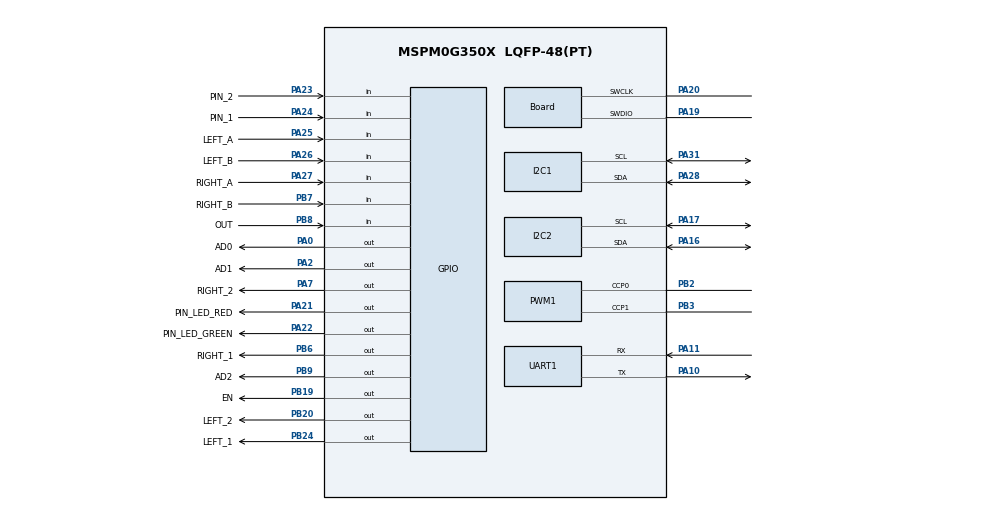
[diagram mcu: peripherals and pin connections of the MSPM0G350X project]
/**
 *
 * @cliArgs --device "MSPM0G350X" --part "Default" --package "LQFP-48(PT)" --product "mspm0_sdk@2.11.00.07"
 * @versions {"tool":"1.28.0+4696"}
 */

/**
 * Import the modules used in this configuration.
 */
const ADC12  = scripting.addModule("/ti/driverlib/ADC12", {}, false);
const ADC121 = ADC12.addInstance();
const GPIO   = scripting.addModule("/ti/driverlib/GPIO", {}, false);
const GPIO1  = GPIO.addInstance();
const GPIO2  = GPIO.addInstance();
const GPIO3  = GPIO.addInstance();
const GPIO4  = GPIO.addInstance();
const GPIO5  = GPIO.addInstance();
const I2C    = scripting.addModule("/ti/driverlib/I2C", {}, false);
const I2C1   = I2C.addInstance();
const I2C2   = I2C.addInstance();
const PWM    = scripting.addModule("/ti/driverlib/PWM", {}, false);
const PWM1   = PWM.addInstance();
const SYSCTL = scripting.addModule("/ti/driverlib/SYSCTL");
const TIMER  = scripting.addModule("/ti/driverlib/TIMER", {}, false);
const TIMER1 = TIMER.addInstance();
const UART   = scripting.addModule("/ti/driverlib/UART", {}, false);
const UART1  = UART.addInstance();

/**
 * Write custom configuration values to the imported modules.
 */
const divider7       = system.clockTree["PLL_PDIV"];
divider7.divideValue = 2;

const divider9       = system.clockTree["UDIV"];
divider9.divideValue = 2;

const multiplier2         = system.clockTree["PLL_QDIV"];
multiplier2.multiplyValue = 5;

const mux8       = system.clockTree["HSCLKMUX"];
mux8.inputSelect = "HSCLKMUX_SYSPLL2X";

ADC121.$name                      = "ADC12_0";
ADC121.peripheral.$assign         = "ADC1";
ADC121.peripheral.adcPin0.$assign = "PA15";
ADC121.adcPin0Config.$name        = "ti_driverlib_gpio_GPIOPinGeneric6";

const Board                       = scripting.addModule("/ti/driverlib/Board", {}, false);
Board.peripheral.$assign          = "DEBUGSS";
Board.peripheral.swclkPin.$assign = "PA20";
Board.peripheral.swdioPin.$assign = "PA19";

GPIO1.$name                              = "GPIO_BUTTON";
GPIO1.associatedPins.create(2);
GPIO1.associatedPins[0].direction        = "INPUT";
GPIO1.associatedPins[0].internalResistor = "PULL_UP";
GPIO1.associatedPins[0].interruptEn      = true;
GPIO1.associatedPins[0].polarity         = "FALL";
GPIO1.associatedPins[0].$name            = "PIN_1";
GPIO1.associatedPins[0].pin.$assign      = "PA24";
GPIO1.associatedPins[1].direction        = "INPUT";
GPIO1.associatedPins[1].internalResistor = "PULL_UP";
GPIO1.associatedPins[1].interruptEn      = true;
GPIO1.associatedPins[1].polarity         = "FALL";
GPIO1.associatedPins[1].$name            = "PIN_2";
GPIO1.associatedPins[1].pin.$assign      = "PA23";

GPIO2.$name                         = "GPIO_LED";
GPIO2.associatedPins.create(2);
GPIO2.associatedPins[0].$name       = "PIN_LED_RED";
GPIO2.associatedPins[0].pin.$assign = "PA21";
GPIO2.associatedPins[1].$name       = "PIN_LED_GREEN";
GPIO2.associatedPins[1].pin.$assign = "PA22";

GPIO3.$name                         = "GPIO_MOTOR";
GPIO3.associatedPins.create(5);
GPIO3.associatedPins[0].$name       = "LEFT_1";
GPIO3.associatedPins[0].pin.$assign = "PB24";
GPIO3.associatedPins[1].$name       = "LEFT_2";
GPIO3.associatedPins[1].pin.$assign = "PB20";
GPIO3.associatedPins[2].$name       = "RIGHT_1";
GPIO3.associatedPins[2].pin.$assign = "PB6";
GPIO3.associatedPins[3].$name       = "RIGHT_2";
GPIO3.associatedPins[3].pin.$assign = "PA7";
GPIO3.associatedPins[4].$name       = "EN";
GPIO3.associatedPins[4].pin.$assign = "PB19";

GPIO4.$name                              = "GPIO_ENCODER";
GPIO4.associatedPins.create(4);
GPIO4.associatedPins[0].direction        = "INPUT";
GPIO4.associatedPins[0].internalResistor = "PULL_UP";
GPIO4.associatedPins[0].interruptEn      = true;
GPIO4.associatedPins[0].polarity         = "FALL";
GPIO4.associatedPins[0].$name            = "LEFT_A";
GPIO4.associatedPins[0].pin.$assign      = "PA25";
GPIO4.associatedPins[1].direction        = "INPUT";
GPIO4.associatedPins[1].internalResistor = "PULL_UP";
GPIO4.associatedPins[1].polarity         = "FALL";
GPIO4.associatedPins[1].$name            = "LEFT_B";
GPIO4.associatedPins[1].pin.$assign      = "PA26";
GPIO4.associatedPins[2].direction        = "INPUT";
GPIO4.associatedPins[2].internalResistor = "PULL_UP";
GPIO4.associatedPins[2].interruptEn      = true;
GPIO4.associatedPins[2].polarity         = "FALL";
GPIO4.associatedPins[2].$name            = "RIGHT_A";
GPIO4.associatedPins[2].pin.$assign      = "PA27";
GPIO4.associatedPins[3].direction        = "INPUT";
GPIO4.associatedPins[3].internalResistor = "PULL_UP";
GPIO4.associatedPins[3].polarity         = "FALL";
GPIO4.associatedPins[3].$name            = "RIGHT_B";
GPIO4.associatedPins[3].pin.$assign      = "PB7";

GPIO5.$name                         = "GPIO_GRAY";
GPIO5.associatedPins.create(4);
GPIO5.associatedPins[0].$name       = "AD0";
GPIO5.associatedPins[0].pin.$assign = "PA0";
GPIO5.associatedPins[1].$name       = "AD1";
GPIO5.associatedPins[1].pin.$assign = "PA2";
GPIO5.associatedPins[2].$name       = "AD2";
GPIO5.associatedPins[2].pin.$assign = "PB9";
GPIO5.associatedPins[3].$name       = "OUT";
GPIO5.associatedPins[3].direction   = "INPUT";
GPIO5.associatedPins[3].pin.$assign = "PB8";

I2C1.$name                             = "I2C_OLED";
I2C1.basicEnableController             = true;
I2C1.basicControllerStandardBusSpeed   = "Fast";
I2C1.peripheral.$assign                = "I2C0";
I2C1.peripheral.sdaPin.$assign         = "PA28";
I2C1.peripheral.sclPin.$assign         = "PA31";
I2C1.sdaPinConfig.hideOutputInversion  = scripting.forceWrite(false);
I2C1.sdaPinConfig.onlyInternalResistor = scripting.forceWrite(false);
I2C1.sdaPinConfig.passedPeripheralType = scripting.forceWrite("Digital");
I2C1.sdaPinConfig.$name                = "ti_driverlib_gpio_GPIOPinGeneric0";
I2C1.sclPinConfig.hideOutputInversion  = scripting.forceWrite(false);
I2C1.sclPinConfig.onlyInternalResistor = scripting.forceWrite(false);
I2C1.sclPinConfig.passedPeripheralType = scripting.forceWrite("Digital");
I2C1.sclPinConfig.$name                = "ti_driverlib_gpio_GPIOPinGeneric1";

I2C2.$name                             = "I2C_GRAY";
I2C2.basicEnableController             = true;
I2C2.basicControllerStandardBusSpeed   = "Fast";
I2C2.peripheral.$assign                = "I2C1";
I2C2.peripheral.sdaPin.$assign         = "PA16";
I2C2.peripheral.sclPin.$assign         = "PA17";
I2C2.sdaPinConfig.$name                = "ti_driverlib_gpio_GPIOPinGeneric7";
I2C2.sdaPinConfig.hideOutputInversion  = scripting.forceWrite(false);
I2C2.sdaPinConfig.onlyInternalResistor = scripting.forceWrite(false);
I2C2.sdaPinConfig.passedPeripheralType = scripting.forceWrite("Digital");
I2C2.sclPinConfig.$name                = "ti_driverlib_gpio_GPIOPinGeneric8";
I2C2.sclPinConfig.hideOutputInversion  = scripting.forceWrite(false);
I2C2.sclPinConfig.onlyInternalResistor = scripting.forceWrite(false);
I2C2.sclPinConfig.passedPeripheralType = scripting.forceWrite("Digital");

PWM1.$name                              = "PWM_MOTOR";
PWM1.pwmMode                            = "EDGE_ALIGN_UP";
PWM1.clockDivider                       = 8;
PWM1.peripheral.$assign                 = "TIMG6";
PWM1.peripheral.ccp0Pin.$assign         = "PB2";
PWM1.peripheral.ccp1Pin.$assign         = "PB3";
PWM1.PWM_CHANNEL_0.$name                = "ti_driverlib_pwm_PWMTimerCC0";
PWM1.PWM_CHANNEL_1.$name                = "ti_driverlib_pwm_PWMTimerCC1";
PWM1.ccp0PinConfig.direction            = scripting.forceWrite("OUTPUT");
PWM1.ccp0PinConfig.hideOutputInversion  = scripting.forceWrite(false);
PWM1.ccp0PinConfig.onlyInternalResistor = scripting.forceWrite(false);
PWM1.ccp0PinConfig.passedPeripheralType = scripting.forceWrite("Digital");
PWM1.ccp0PinConfig.$name                = "ti_driverlib_gpio_GPIOPinGeneric2";
PWM1.ccp1PinConfig.direction            = scripting.forceWrite("OUTPUT");
PWM1.ccp1PinConfig.hideOutputInversion  = scripting.forceWrite(false);
PWM1.ccp1PinConfig.onlyInternalResistor = scripting.forceWrite(false);
PWM1.ccp1PinConfig.passedPeripheralType = scripting.forceWrite("Digital");
PWM1.ccp1PinConfig.$name                = "ti_driverlib_gpio_GPIOPinGeneric3";

SYSCTL.forceDefaultClkConfig = true;
SYSCTL.clockTreeEn           = true;

TIMER1.$name            = "Motor_PID";
TIMER1.timerMode        = "PERIODIC_UP";
TIMER1.timerPeriod      = "50 ms";
TIMER1.timerClkPrescale = 100;
TIMER1.interrupts       = ["LOAD"];

UART1.$name                            = "UART_PC";
UART1.targetBaudRate                   = 115200;
UART1.peripheral.$assign               = "UART0";
UART1.peripheral.rxPin.$assign         = "PA11";
UART1.peripheral.txPin.$assign         = "PA10";
UART1.txPinConfig.direction            = scripting.forceWrite("OUTPUT");
UART1.txPinConfig.hideOutputInversion  = scripting.forceWrite(false);
UART1.txPinConfig.onlyInternalResistor = scripting.forceWrite(false);
UART1.txPinConfig.passedPeripheralType = scripting.forceWrite("Digital");
UART1.txPinConfig.$name                = "ti_driverlib_gpio_GPIOPinGeneric4";
UART1.rxPinConfig.hideOutputInversion  = scripting.forceWrite(false);
UART1.rxPinConfig.onlyInternalResistor = scripting.forceWrite(false);
UART1.rxPinConfig.passedPeripheralType = scripting.forceWrite("Digital");
UART1.rxPinConfig.$name                = "ti_driverlib_gpio_GPIOPinGeneric5";

const ProjectConfig              = scripting.addModule("/ti/project_config/ProjectConfig", {}, false);
ProjectConfig.migrationCondition = true;

/**
 * Pinmux solution for unlocked pins/peripherals. This ensures that minor changes to the automatic solver in a future
 * version of the tool will not impact the pinmux you originally saw.  These lines can be completely deleted in order to
 * re-solve from scratch.
 */
TIMER1.peripheral.$suggestSolution = "TIMA0";
